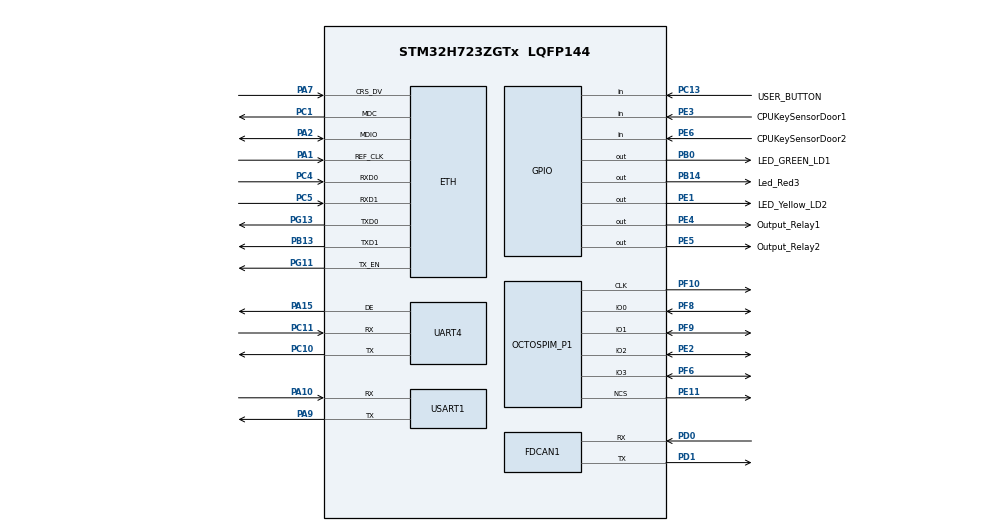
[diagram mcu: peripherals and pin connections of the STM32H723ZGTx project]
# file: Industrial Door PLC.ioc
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CORTEX_M7.AccessPermission_S-Cortex_Memory_Protection_Unit_Region1_Settings_S=MPU_REGION_PRIV_RO
CORTEX_M7.BaseAddress_S-Cortex_Memory_Protection_Unit_Region1_Settings_S=0x08000000
CORTEX_M7.Enable_S-Cortex_Memory_Protection_Unit_Region1_Settings_S=MPU_REGION_ENABLE
CORTEX_M7.IsCacheable_S-Cortex_Memory_Protection_Unit_Region1_Settings_S=MPU_ACCESS_CACHEABLE
CORTEX_M7.Size_S-Cortex_Memory_Protection_Unit_Region1_Settings_S=MPU_REGION_SIZE_1MB
CORTEX_M7.TypeExtField_S-Cortex_Memory_Protection_Unit_Region1_Settings_S=MPU_TEX_LEVEL1
CORTEX_M7.default_mode_Activation=1
ETH.MediaInterface=HAL_ETH_RMII_MODE
FDCAN1.CalculateBaudRateNominal=1000000
FDCAN1.CalculateTimeQuantumNominal=333.3333333333333
Mcu.Family=STM32H7
Mcu.Name=STM32H723ZGTx
Mcu.Package=LQFP144
NUCLEO-H723ZG.VCP=true
NVIC.PriorityGroup=NVIC_PRIORITYGROUP_4
PA1.Mode=RMII
PA1.Signal=ETH_REF_CLK
PA10.Mode=Asynchronous
PA10.Signal=USART1_RX
PA13(JTMS/SWDIO).Mode=Serial_Wire
PA13(JTMS/SWDIO).Signal=DEBUG_JTMS-SWDIO
PA14(JTCK/SWCLK).Mode=Serial_Wire
PA14(JTCK/SWCLK).Signal=DEBUG_JTCK-SWCLK
PA15(JTDI).Mode=Hardware Flow Control (RS485)
PA15(JTDI).Signal=UART4_DE
PA2.Mode=RMII
PA2.Signal=ETH_MDIO
PA7.Mode=RMII
PA7.Signal=ETH_CRS_DV
PA9.Mode=Asynchronous
PA9.Signal=USART1_TX
PB0.GPIO_Label=LED_GREEN_LD1
PB0.PinState=GPIO_PIN_RESET
PB0.Signal=GPIO_Output
PB13.Mode=RMII
PB13.Signal=ETH_TXD1
PB14.GPIO_Label=Led_Red3
PB14.PinState=GPIO_PIN_RESET
PB14.Signal=GPIO_Output
PC1.Mode=RMII
PC1.Signal=ETH_MDC
PC10.Mode=Asynchronous
PC10.Signal=UART4_TX
PC11.Mode=Asynchronous
PC11.Signal=UART4_RX
PC13.GPIO_Label=USER_BUTTON
PC13.GPIO_PuPd=GPIO_PULLDOWN
PC13.Signal=GPIO_Input
PC14-OSC32_IN.Mode=LSE-External-Oscillator
PC14-OSC32_IN.Signal=RCC_OSC32_IN
PC15-OSC32_OUT.Mode=LSE-External-Oscillator
PC15-OSC32_OUT.Signal=RCC_OSC32_OUT
PC4.Mode=RMII
PC4.Signal=ETH_RXD0
PC5.Mode=RMII
PC5.Signal=ETH_RXD1
PD0.Mode=FDCAN_Activate
PD0.Signal=FDCAN1_RX
PD1.Mode=FDCAN_Activate
PD1.Signal=FDCAN1_TX
PE1.GPIO_Label=LED_Yellow_LD2
PE1.PinState=GPIO_PIN_RESET
PE1.Signal=GPIO_Output
PE11.Mode=OCTOSPI1_Port1_NCS
PE11.Signal=OCTOSPIM_P1_NCS
PE2.Mode=OCTOSPI1_IOL_Port1L
PE2.Signal=OCTOSPIM_P1_IO2
PE3.GPIO_Label=CPUKeySensorDoor1
PE3.GPIO_PuPd=GPIO_PULLUP
PE3.Signal=GPIO_Input
PE4.GPIO_Label=Output_Relay1
PE4.PinState=GPIO_PIN_SET
PE4.Signal=GPIO_Output
PE5.GPIO_Label=Output_Relay2
PE5.PinState=GPIO_PIN_SET
PE5.Signal=GPIO_Output
PE6.GPIO_Label=CPUKeySensorDoor2
PE6.GPIO_PuPd=GPIO_PULLUP
PE6.Signal=GPIO_Input
PF10.Mode=O1_P1_CLK
PF10.Signal=OCTOSPIM_P1_CLK
PF6.Mode=OCTOSPI1_IOL_Port1L
PF6.Signal=OCTOSPIM_P1_IO3
PF8.Mode=OCTOSPI1_IOL_Port1L
PF8.Signal=OCTOSPIM_P1_IO0
PF9.Mode=OCTOSPI1_IOL_Port1L
PF9.Signal=OCTOSPIM_P1_IO1
PG11.Mode=RMII
PG11.Signal=ETH_TX_EN
PG13.Mode=RMII
PG13.Signal=ETH_TXD0
ProjectManager.HeapSize=0x200
ProjectManager.StackSize=0x400
ProjectManager.TargetToolchain=STM32CubeIDE
RCC.ADCFreq_Value=608000000
RCC.APB1Freq_Value=48000000
RCC.APB2Freq_Value=48000000
RCC.APB3Freq_Value=48000000
RCC.APB4Freq_Value=48000000
RCC.CortexFreq_Value=192000000
RCC.D1PPRE=RCC_APB3_DIV2
RCC.D2PPRE1=RCC_APB1_DIV2
RCC.D2PPRE2=RCC_APB2_DIV2
RCC.D3PPRE=RCC_APB4_DIV2
RCC.DIVM1=4
RCC.DIVM2=1
RCC.DIVN1=12
RCC.DIVN2=19
RCC.DIVP1=1
RCC.DIVQ1=4
RCC.HCLKFreq_Value=96000000
RCC.HPRE=RCC_HCLK_DIV2
RCC.HSE_VALUE=8000000
RCC.PLLFRACN=0
RCC.SYSCLKFreq_VALUE=192000000
RCC.SYSCLKSource=RCC_SYSCLKSOURCE_PLLCLK
RCC.USBCLockSelection=RCC_USBCLKSOURCE_HSI48
RCC.USBFreq_Value=48000000
USART1.VirtualMode-Asynchronous=VM_ASYNC
VP_MEMORYMAP_VS_MEMORYMAP.Mode=CurAppReg
VP_OCTOSPI1_VS_quad.Mode=quad_mode
board=NUCLEO-H723ZG

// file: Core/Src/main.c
/* USER CODE BEGIN Header */
/**
  ******************************************************************************
  * @file           : main.c
  * @brief          : Main program body
  ******************************************************************************
  * @attention
  *
  * Copyright (c) 2025 STMicroelectronics.
  * All rights reserved.
  *
  * This software is licensed under terms that can be found in the LICENSE file
  * in the root directory of this software component.
  * If no LICENSE file comes with this software, it is provided AS-IS.
  *
  ******************************************************************************
  */
/* USER CODE END Header */
#include "main.h"
#include "string.h"

/* USER CODE BEGIN Includes */

//Подключение моих функций
//================================================================================================================
#include "my_function.h"

//Подключение моих функций
//================================================================================================================

/* USER CODE END Includes */

#if defined ( __ICCARM__ ) /*!< IAR Compiler */
#pragma location=0x30000000
ETH_DMADescTypeDef  DMARxDscrTab[ETH_RX_DESC_CNT]; /* Ethernet Rx DMA Descriptors */
#pragma location=0x30000080
ETH_DMADescTypeDef  DMATxDscrTab[ETH_TX_DESC_CNT]; /* Ethernet Tx DMA Descriptors */

#elif defined ( __CC_ARM )  /* MDK ARM Compiler */

__attribute__((at(0x30000000))) ETH_DMADescTypeDef  DMARxDscrTab[ETH_RX_DESC_CNT]; /* Ethernet Rx DMA Descriptors */
__attribute__((at(0x30000080))) ETH_DMADescTypeDef  DMATxDscrTab[ETH_TX_DESC_CNT]; /* Ethernet Tx DMA Descriptors */

#elif defined ( __GNUC__ ) /* GNU Compiler */

ETH_DMADescTypeDef DMARxDscrTab[ETH_RX_DESC_CNT] __attribute__((section(".RxDescripSection"))); /* Ethernet Rx DMA Descriptors */
ETH_DMADescTypeDef DMATxDscrTab[ETH_TX_DESC_CNT] __attribute__((section(".TxDescripSection")));   /* Ethernet Tx DMA Descriptors */
#endif

ETH_TxPacketConfig TxConfig;

ETH_HandleTypeDef heth;

FDCAN_HandleTypeDef hfdcan1;

OSPI_HandleTypeDef hospi1;

UART_HandleTypeDef huart4;
UART_HandleTypeDef huart1;

void SystemClock_Config(void);
static void MPU_Config(void);
static void MX_GPIO_Init(void);
static void MX_ETH_Init(void);
static void MX_FDCAN1_Init(void);
static void MX_OCTOSPI1_Init(void);
static void MX_UART4_Init(void);
static void MX_USART1_UART_Init(void);
/* USER CODE BEGIN PFP */

//Декларация Моих Функций
//=============================================================================================================

//Декларация Моих Функций
//=============================================================================================================

/* USER CODE END PFP */

int main(void)
{

  /* MPU Configuration--------------------------------------------------------*/
  MPU_Config();

  /* MCU Configuration--------------------------------------------------------*/

  /* Reset of all peripherals, Initializes the Flash interface and the Systick. */
  HAL_Init();

  /* Configure the system clock */
  SystemClock_Config();

  /* Initialize all configured peripherals */
  MX_GPIO_Init();
  MX_ETH_Init();
  MX_FDCAN1_Init();
  MX_OCTOSPI1_Init();
  MX_UART4_Init();
  MX_USART1_UART_Init();

  /* Infinite loop */
  /* USER CODE BEGIN WHILE */
  //=================================================================================Программа===================
  while (1)
  {
	  if((HAL_GPIO_ReadPin(CPUKeySensorDoor1_GPIO_Port, CPUKeySensorDoor1_Pin)==0) && (HAL_GPIO_ReadPin(CPUKeySensorDoor2_GPIO_Port, CPUKeySensorDoor2_Pin)==0))
	  {
		  Open_Door1();
		  Open_Door2();
	  }
	  else if(HAL_GPIO_ReadPin(CPUKeySensorDoor1_GPIO_Port, CPUKeySensorDoor1_Pin)!=0){

			  Close_Door2();
		  }
		  else {

				  Close_Door1();
			  }

/*

	 if(HAL_GPIO_ReadPin(CPUKeySensorDoor2_GPIO_Port, CPUKeySensorDoor2_Pin)==0)
	  	  {

		 Close_Door2();
	  	  }
	  	  else{
	  		Open_Door2();

	  	  }
*/
	  //=================================================================================Программа===============

    /* USER CODE END WHILE */

  }
}

void SystemClock_Config(void)
{
  RCC_OscInitTypeDef RCC_OscInitStruct = {0};
  RCC_ClkInitTypeDef RCC_ClkInitStruct = {0};

  /** Supply configuration update enable
  */
  HAL_PWREx_ConfigSupply(PWR_LDO_SUPPLY);

  /** Configure the main internal regulator output voltage
  */
  __HAL_PWR_VOLTAGESCALING_CONFIG(PWR_REGULATOR_VOLTAGE_SCALE2);

  while(!__HAL_PWR_GET_FLAG(PWR_FLAG_VOSRDY)) {}

  /** Initializes the RCC Oscillators according to the specified parameters
  * in the RCC_OscInitTypeDef structure.
  */
  RCC_OscInitStruct.OscillatorType = RCC_OSCILLATORTYPE_HSI;
  RCC_OscInitStruct.HSIState = RCC_HSI_DIV1;
  RCC_OscInitStruct.HSICalibrationValue = 64;
  RCC_OscInitStruct.PLL.PLLState = RCC_PLL_ON;
  RCC_OscInitStruct.PLL.PLLSource = RCC_PLLSOURCE_HSI;
  RCC_OscInitStruct.PLL.PLLM = 4;
  RCC_OscInitStruct.PLL.PLLN = 12;
  RCC_OscInitStruct.PLL.PLLP = 1;
  RCC_OscInitStruct.PLL.PLLQ = 4;
  RCC_OscInitStruct.PLL.PLLR = 2;
  RCC_OscInitStruct.PLL.PLLRGE = RCC_PLL1VCIRANGE_3;
  RCC_OscInitStruct.PLL.PLLVCOSEL = RCC_PLL1VCOWIDE;
  RCC_OscInitStruct.PLL.PLLFRACN = 0;
  if (HAL_RCC_OscConfig(&RCC_OscInitStruct) != HAL_OK)
  {
    Error_Handler();
  }

  /** Initializes the CPU, AHB and APB buses clocks
  */
  RCC_ClkInitStruct.ClockType = RCC_CLOCKTYPE_HCLK|RCC_CLOCKTYPE_SYSCLK
                              |RCC_CLOCKTYPE_PCLK1|RCC_CLOCKTYPE_PCLK2
                              |RCC_CLOCKTYPE_D3PCLK1|RCC_CLOCKTYPE_D1PCLK1;
  RCC_ClkInitStruct.SYSCLKSource = RCC_SYSCLKSOURCE_PLLCLK;
  RCC_ClkInitStruct.SYSCLKDivider = RCC_SYSCLK_DIV1;
  RCC_ClkInitStruct.AHBCLKDivider = RCC_HCLK_DIV2;
  RCC_ClkInitStruct.APB3CLKDivider = RCC_APB3_DIV2;
  RCC_ClkInitStruct.APB1CLKDivider = RCC_APB1_DIV2;
  RCC_ClkInitStruct.APB2CLKDivider = RCC_APB2_DIV2;
  RCC_ClkInitStruct.APB4CLKDivider = RCC_APB4_DIV2;

  if (HAL_RCC_ClockConfig(&RCC_ClkInitStruct, FLASH_LATENCY_1) != HAL_OK)
  {
    Error_Handler();
  }
}

static void MX_ETH_Init(void)
{

   static uint8_t MACAddr[6];

  heth.Instance = ETH;
  MACAddr[0] = 0x00;
  MACAddr[1] = 0x80;
  MACAddr[2] = 0xE1;
  MACAddr[3] = 0x00;
  MACAddr[4] = 0x00;
  MACAddr[5] = 0x00;
  heth.Init.MACAddr = &MACAddr[0];
  heth.Init.MediaInterface = HAL_ETH_RMII_MODE;
  heth.Init.TxDesc = DMATxDscrTab;
  heth.Init.RxDesc = DMARxDscrTab;
  heth.Init.RxBuffLen = 1536;

  if (HAL_ETH_Init(&heth) != HAL_OK)
  {
    Error_Handler();
  }

  memset(&TxConfig, 0 , sizeof(ETH_TxPacketConfig));
  TxConfig.Attributes = ETH_TX_PACKETS_FEATURES_CSUM | ETH_TX_PACKETS_FEATURES_CRCPAD;
  TxConfig.ChecksumCtrl = ETH_CHECKSUM_IPHDR_PAYLOAD_INSERT_PHDR_CALC;
  TxConfig.CRCPadCtrl = ETH_CRC_PAD_INSERT;

}

static void MX_FDCAN1_Init(void)
{

  hfdcan1.Instance = FDCAN1;
  hfdcan1.Init.FrameFormat = FDCAN_FRAME_CLASSIC;
  hfdcan1.Init.Mode = FDCAN_MODE_NORMAL;
  hfdcan1.Init.AutoRetransmission = DISABLE;
  hfdcan1.Init.TransmitPause = DISABLE;
  hfdcan1.Init.ProtocolException = DISABLE;
  hfdcan1.Init.NominalPrescaler = 16;
  hfdcan1.Init.NominalSyncJumpWidth = 1;
  hfdcan1.Init.NominalTimeSeg1 = 1;
  hfdcan1.Init.NominalTimeSeg2 = 1;
  hfdcan1.Init.DataPrescaler = 1;
  hfdcan1.Init.DataSyncJumpWidth = 1;
  hfdcan1.Init.DataTimeSeg1 = 1;
  hfdcan1.Init.DataTimeSeg2 = 1;
  hfdcan1.Init.MessageRAMOffset = 0;
  hfdcan1.Init.StdFiltersNbr = 0;
  hfdcan1.Init.ExtFiltersNbr = 0;
  hfdcan1.Init.RxFifo0ElmtsNbr = 0;
  hfdcan1.Init.RxFifo0ElmtSize = FDCAN_DATA_BYTES_8;
  hfdcan1.Init.RxFifo1ElmtsNbr = 0;
  hfdcan1.Init.RxFifo1ElmtSize = FDCAN_DATA_BYTES_8;
  hfdcan1.Init.RxBuffersNbr = 0;
  hfdcan1.Init.RxBufferSize = FDCAN_DATA_BYTES_8;
  hfdcan1.Init.TxEventsNbr = 0;
  hfdcan1.Init.TxBuffersNbr = 0;
  hfdcan1.Init.TxFifoQueueElmtsNbr = 0;
  hfdcan1.Init.TxFifoQueueMode = FDCAN_TX_FIFO_OPERATION;
  hfdcan1.Init.TxElmtSize = FDCAN_DATA_BYTES_8;
  if (HAL_FDCAN_Init(&hfdcan1) != HAL_OK)
  {
    Error_Handler();
  }

}

static void MX_OCTOSPI1_Init(void)
{

  OSPIM_CfgTypeDef sOspiManagerCfg = {0};

  /* OCTOSPI1 parameter configuration*/
  hospi1.Instance = OCTOSPI1;
  hospi1.Init.FifoThreshold = 1;
  hospi1.Init.DualQuad = HAL_OSPI_DUALQUAD_DISABLE;
  hospi1.Init.MemoryType = HAL_OSPI_MEMTYPE_MICRON;
  hospi1.Init.DeviceSize = 32;
  hospi1.Init.ChipSelectHighTime = 1;
  hospi1.Init.FreeRunningClock = HAL_OSPI_FREERUNCLK_DISABLE;
  hospi1.Init.ClockMode = HAL_OSPI_CLOCK_MODE_0;
  hospi1.Init.WrapSize = HAL_OSPI_WRAP_NOT_SUPPORTED;
  hospi1.Init.ClockPrescaler = 1;
  hospi1.Init.SampleShifting = HAL_OSPI_SAMPLE_SHIFTING_NONE;
  hospi1.Init.DelayHoldQuarterCycle = HAL_OSPI_DHQC_DISABLE;
  hospi1.Init.ChipSelectBoundary = 0;
  hospi1.Init.DelayBlockBypass = HAL_OSPI_DELAY_BLOCK_BYPASSED;
  hospi1.Init.MaxTran = 0;
  hospi1.Init.Refresh = 0;
  if (HAL_OSPI_Init(&hospi1) != HAL_OK)
  {
    Error_Handler();
  }
  sOspiManagerCfg.ClkPort = 1;
  sOspiManagerCfg.NCSPort = 1;
  sOspiManagerCfg.IOLowPort = HAL_OSPIM_IOPORT_1_LOW;
  if (HAL_OSPIM_Config(&hospi1, &sOspiManagerCfg, HAL_OSPI_TIMEOUT_DEFAULT_VALUE) != HAL_OK)
  {
    Error_Handler();
  }

}

static void MX_UART4_Init(void)
{

  huart4.Instance = UART4;
  huart4.Init.BaudRate = 115200;
  huart4.Init.WordLength = UART_WORDLENGTH_8B;
  huart4.Init.StopBits = UART_STOPBITS_1;
  huart4.Init.Parity = UART_PARITY_NONE;
  huart4.Init.Mode = UART_MODE_TX_RX;
  huart4.Init.HwFlowCtl = UART_HWCONTROL_NONE;
  huart4.Init.OverSampling = UART_OVERSAMPLING_16;
  huart4.Init.OneBitSampling = UART_ONE_BIT_SAMPLE_DISABLE;
  huart4.Init.ClockPrescaler = UART_PRESCALER_DIV1;
  huart4.AdvancedInit.AdvFeatureInit = UART_ADVFEATURE_NO_INIT;
  if (HAL_RS485Ex_Init(&huart4, UART_DE_POLARITY_HIGH, 0, 0) != HAL_OK)
  {
    Error_Handler();
  }
  if (HAL_UARTEx_SetTxFifoThreshold(&huart4, UART_TXFIFO_THRESHOLD_1_8) != HAL_OK)
  {
    Error_Handler();
  }
  if (HAL_UARTEx_SetRxFifoThreshold(&huart4, UART_RXFIFO_THRESHOLD_1_8) != HAL_OK)
  {
    Error_Handler();
  }
  if (HAL_UARTEx_DisableFifoMode(&huart4) != HAL_OK)
  {
    Error_Handler();
  }

}

static void MX_USART1_UART_Init(void)
{

  huart1.Instance = USART1;
  huart1.Init.BaudRate = 115200;
  huart1.Init.WordLength = UART_WORDLENGTH_8B;
  huart1.Init.StopBits = UART_STOPBITS_1;
  huart1.Init.Parity = UART_PARITY_NONE;
  huart1.Init.Mode = UART_MODE_TX_RX;
  huart1.Init.HwFlowCtl = UART_HWCONTROL_NONE;
  huart1.Init.OverSampling = UART_OVERSAMPLING_16;
  huart1.Init.OneBitSampling = UART_ONE_BIT_SAMPLE_DISABLE;
  huart1.Init.ClockPrescaler = UART_PRESCALER_DIV1;
  huart1.AdvancedInit.AdvFeatureInit = UART_ADVFEATURE_NO_INIT;
  if (HAL_UART_Init(&huart1) != HAL_OK)
  {
    Error_Handler();
  }
  if (HAL_UARTEx_SetTxFifoThreshold(&huart1, UART_TXFIFO_THRESHOLD_1_8) != HAL_OK)
  {
    Error_Handler();
  }
  if (HAL_UARTEx_SetRxFifoThreshold(&huart1, UART_RXFIFO_THRESHOLD_1_8) != HAL_OK)
  {
    Error_Handler();
  }
  if (HAL_UARTEx_DisableFifoMode(&huart1) != HAL_OK)
  {
    Error_Handler();
  }

}

static void MX_GPIO_Init(void)
{
  GPIO_InitTypeDef GPIO_InitStruct = {0};

  /* GPIO Ports Clock Enable */
  __HAL_RCC_GPIOE_CLK_ENABLE();
  __HAL_RCC_GPIOC_CLK_ENABLE();
  __HAL_RCC_GPIOF_CLK_ENABLE();
  __HAL_RCC_GPIOA_CLK_ENABLE();
  __HAL_RCC_GPIOB_CLK_ENABLE();
  __HAL_RCC_GPIOD_CLK_ENABLE();
  __HAL_RCC_GPIOG_CLK_ENABLE();

  /*Configure GPIO pin Output Level */
  HAL_GPIO_WritePin(GPIOE, Output_Relay1_Pin|Output_Relay2_Pin, GPIO_PIN_SET);

  /*Configure GPIO pin Output Level */
  HAL_GPIO_WritePin(GPIOB, LED_GREEN_LD1_Pin|Led_Red3_Pin, GPIO_PIN_RESET);

  /*Configure GPIO pin Output Level */
  HAL_GPIO_WritePin(LED_Yellow_LD2_GPIO_Port, LED_Yellow_LD2_Pin, GPIO_PIN_RESET);

  /*Configure GPIO pins : CPUKeySensorDoor1_Pin CPUKeySensorDoor2_Pin */
  GPIO_InitStruct.Pin = CPUKeySensorDoor1_Pin|CPUKeySensorDoor2_Pin;
  GPIO_InitStruct.Mode = GPIO_MODE_INPUT;
  GPIO_InitStruct.Pull = GPIO_PULLUP;
  HAL_GPIO_Init(GPIOE, &GPIO_InitStruct);

  /*Configure GPIO pins : Output_Relay1_Pin Output_Relay2_Pin LED_Yellow_LD2_Pin */
  GPIO_InitStruct.Pin = Output_Relay1_Pin|Output_Relay2_Pin|LED_Yellow_LD2_Pin;
  GPIO_InitStruct.Mode = GPIO_MODE_OUTPUT_PP;
  GPIO_InitStruct.Pull = GPIO_NOPULL;
  GPIO_InitStruct.Speed = GPIO_SPEED_FREQ_LOW;
  HAL_GPIO_Init(GPIOE, &GPIO_InitStruct);

  /*Configure GPIO pin : USER_BUTTON_Pin */
  GPIO_InitStruct.Pin = USER_BUTTON_Pin;
  GPIO_InitStruct.Mode = GPIO_MODE_INPUT;
  GPIO_InitStruct.Pull = GPIO_PULLDOWN;
  HAL_GPIO_Init(USER_BUTTON_GPIO_Port, &GPIO_InitStruct);

  /*Configure GPIO pins : LED_GREEN_LD1_Pin Led_Red3_Pin */
  GPIO_InitStruct.Pin = LED_GREEN_LD1_Pin|Led_Red3_Pin;
  GPIO_InitStruct.Mode = GPIO_MODE_OUTPUT_PP;
  GPIO_InitStruct.Pull = GPIO_NOPULL;
  GPIO_InitStruct.Speed = GPIO_SPEED_FREQ_LOW;
  HAL_GPIO_Init(GPIOB, &GPIO_InitStruct);

}

 /* MPU Configuration */

void MPU_Config(void)
{
  MPU_Region_InitTypeDef MPU_InitStruct = {0};

  /* Disables the MPU */
  HAL_MPU_Disable();

  /** Initializes and configures the Region and the memory to be protected
  */
  MPU_InitStruct.Enable = MPU_REGION_ENABLE;
  MPU_InitStruct.Number = MPU_REGION_NUMBER0;
  MPU_InitStruct.BaseAddress = 0x0;
  MPU_InitStruct.Size = MPU_REGION_SIZE_4GB;
  MPU_InitStruct.SubRegionDisable = 0x87;
  MPU_InitStruct.TypeExtField = MPU_TEX_LEVEL0;
  MPU_InitStruct.AccessPermission = MPU_REGION_NO_ACCESS;
  MPU_InitStruct.DisableExec = MPU_INSTRUCTION_ACCESS_DISABLE;
  MPU_InitStruct.IsShareable = MPU_ACCESS_SHAREABLE;
  MPU_InitStruct.IsCacheable = MPU_ACCESS_NOT_CACHEABLE;
  MPU_InitStruct.IsBufferable = MPU_ACCESS_NOT_BUFFERABLE;

  HAL_MPU_ConfigRegion(&MPU_InitStruct);

  /** Initializes and configures the Region and the memory to be protected
  */
  MPU_InitStruct.Number = MPU_REGION_NUMBER1;
  MPU_InitStruct.BaseAddress = 0x08000000;
  MPU_InitStruct.Size = MPU_REGION_SIZE_1MB;
  MPU_InitStruct.SubRegionDisable = 0x0;
  MPU_InitStruct.TypeExtField = MPU_TEX_LEVEL1;
  MPU_InitStruct.AccessPermission = MPU_REGION_PRIV_RO;
  MPU_InitStruct.DisableExec = MPU_INSTRUCTION_ACCESS_ENABLE;
  MPU_InitStruct.IsShareable = MPU_ACCESS_NOT_SHAREABLE;
  MPU_InitStruct.IsCacheable = MPU_ACCESS_CACHEABLE;

  HAL_MPU_ConfigRegion(&MPU_InitStruct);
  /* Enables the MPU */
  HAL_MPU_Enable(MPU_PRIVILEGED_DEFAULT);

}

void Error_Handler(void)
{
  __disable_irq();
  while (1)
  {
  }
}
